AUTOSAR XML (schema 00044)
package /ComponentTypes
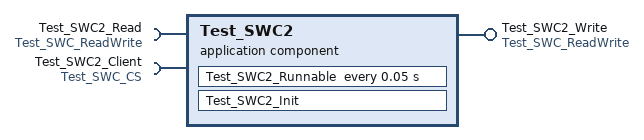
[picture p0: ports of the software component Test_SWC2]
  application sw component type Test_SWC2
    require port Test_SWC2_Read: nonqueued-receiver-com-spec{data-element=Element, init-value=0}, required-interface=Test_SWC_ReadWrite
    provide port Test_SWC2_Write: nonqueued-sender-com-spec{data-element=Element, init-value=0}, provided-interface=Test_SWC_ReadWrite
    require port Test_SWC2_Client: client-com-spec=Operation, required-interface=Test_SWC_CS
    behavior Test_SWC2_InternalBehavior
      timing event TMT_Test_SWC2_Runnable: start-on-event=Test_SWC2_Runnable, period=0.05
      init event Test_SWC2_InitEvent: start-on-event=Test_SWC2_Init
      runnable Test_SWC2_Runnable: minimum-start-interval=0.05
        data-receive-point-by-arguments:
          access REC_Test_SWC2_Read_Element: accessed-variable=Test_SWC2_Read.Element
        data-send-points:
          access SEND_Test_SWC2_Write_Element: accessed-variable=Test_SWC2_Write.Element
        sync call SC_Test_SWC2_Client_Operation: operation=Test_SWC2_Client.Operation
      runnable Test_SWC2_Init
  swc implementation Test_SWC2_Implementation: behavior=Test_SWC2_InternalBehavior
